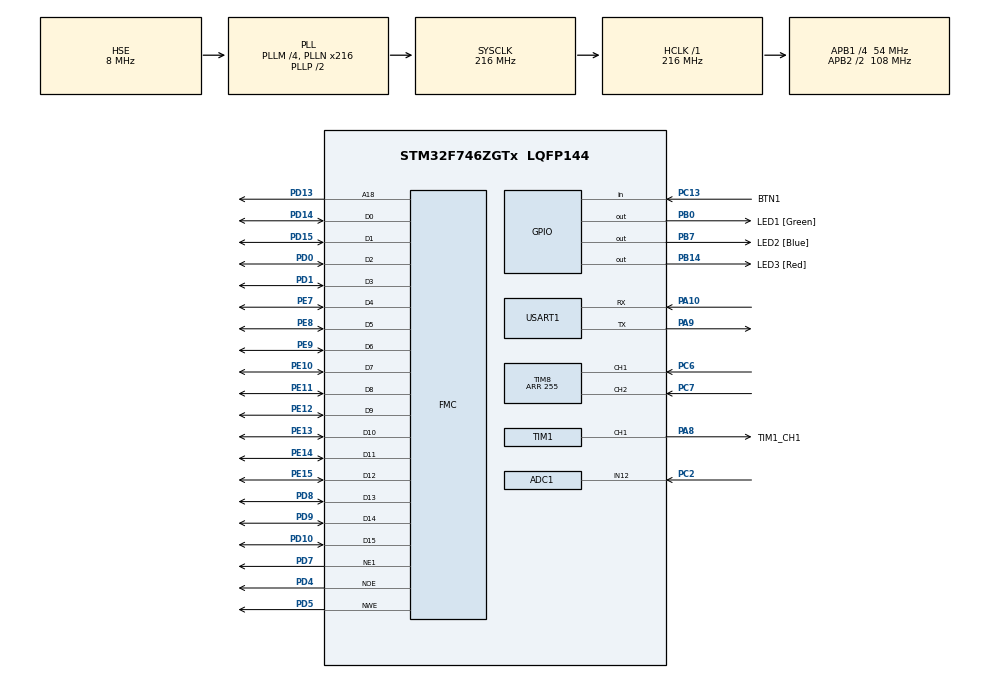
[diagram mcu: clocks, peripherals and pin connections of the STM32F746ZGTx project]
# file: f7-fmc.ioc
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ADC1.Channel-4\#ChannelRegularConversion=ADC_CHANNEL_12
ADC1.ClockPrescaler=ADC_CLOCK_SYNC_PCLK_DIV4
ADC1.ContinuousConvMode=ENABLE
ADC1.DMAContinuousRequests=ENABLE
ADC1.DataAlign=ADC_DATAALIGN_RIGHT
ADC1.DiscontinuousConvMode=DISABLE
ADC1.EOCSelection=ADC_EOC_SINGLE_CONV
ADC1.EnableAnalogWatchDog=false
ADC1.ExternalTrigConv=ADC_SOFTWARE_START
ADC1.ExternalTrigConvEdge=ADC_EXTERNALTRIGCONVEDGE_NONE
ADC1.InjNumberOfConversion=0
ADC1.NbrOfConversion=1
ADC1.NbrOfConversionFlag=1
ADC1.Rank-4\#ChannelRegularConversion=1
ADC1.Resolution=ADC_RESOLUTION_8B
ADC1.SamplingTime-4\#ChannelRegularConversion=ADC_SAMPLETIME_3CYCLES
ADC1.ScanConvMode=ENABLE
ADC1.master=1
CORTEX_M7.CPU_DCache=Disabled
CORTEX_M7.CPU_ICache=Disabled
Dma.ADC1.0.Direction=DMA_PERIPH_TO_MEMORY
Dma.ADC1.0.FIFOMode=DMA_FIFOMODE_DISABLE
Dma.ADC1.0.Instance=DMA2_Stream0
Dma.ADC1.0.MemDataAlignment=DMA_MDATAALIGN_BYTE
Dma.ADC1.0.MemInc=DMA_MINC_ENABLE
Dma.ADC1.0.Mode=DMA_CIRCULAR
Dma.ADC1.0.PeriphDataAlignment=DMA_PDATAALIGN_BYTE
Dma.ADC1.0.PeriphInc=DMA_PINC_DISABLE
Dma.ADC1.0.Priority=DMA_PRIORITY_LOW
Dma.MEMTOMEM.1.Direction=DMA_MEMORY_TO_MEMORY
Dma.MEMTOMEM.1.FIFOMode=DMA_FIFOMODE_ENABLE
Dma.MEMTOMEM.1.FIFOThreshold=DMA_FIFO_THRESHOLD_FULL
Dma.MEMTOMEM.1.Instance=DMA2_Stream1
Dma.MEMTOMEM.1.MemBurst=DMA_MBURST_SINGLE
Dma.MEMTOMEM.1.MemDataAlignment=DMA_MDATAALIGN_HALFWORD
Dma.MEMTOMEM.1.MemInc=DMA_MINC_DISABLE
Dma.MEMTOMEM.1.Mode=DMA_NORMAL
Dma.MEMTOMEM.1.PeriphBurst=DMA_PBURST_SINGLE
Dma.MEMTOMEM.1.PeriphDataAlignment=DMA_PDATAALIGN_HALFWORD
Dma.MEMTOMEM.1.PeriphInc=DMA_PINC_ENABLE
Dma.MEMTOMEM.1.Priority=DMA_PRIORITY_HIGH
Dma.Request0=ADC1
Dma.Request1=MEMTOMEM
FMC.AddressSetupTime1=3
FMC.BusTurnAroundDuration1=3
FMC.DataSetupTime1=8
FMC.ExtendedAddressSetupTime1=3
FMC.ExtendedBusTurnAroundDuration1=3
FMC.ExtendedDataSetupTime1=3
FMC.ExtendedMode1=FMC_EXTENDED_MODE_ENABLE
FMC.WriteFifo1=FMC_WRITE_FIFO_ENABLE
FMC.WriteOperation1=FMC_WRITE_OPERATION_ENABLE
Mcu.Family=STM32F7
Mcu.Name=STM32F746ZGTx
Mcu.Package=LQFP144
NVIC.DMA2_Stream0_IRQn=true\:0\:0\:false\:false\:true\:false
NVIC.PriorityGroup=NVIC_PRIORITYGROUP_4
PA10.Mode=Asynchronous
PA10.Signal=USART1_RX
PA13.GPIO_Label=TMS
PA13.Mode=Trace_Asynchronous_SW
PA13.Signal=SYS_JTMS-SWDIO
PA14.GPIO_Label=TCK
PA14.Mode=Trace_Asynchronous_SW
PA14.Signal=SYS_JTCK-SWCLK
PA8.GPIO_Label=TIM1_CH1
PA8.GPIO_PuPd=GPIO_NOPULL
PA8.GPIO_Speed=GPIO_SPEED_FREQ_VERY_HIGH
PA8.Signal=S_TIM1_CH1
PA9.Mode=Asynchronous
PA9.Signal=USART1_TX
PB0.GPIO_Label=LED1 [Green]
PB0.Signal=GPIO_Output
PB14.GPIO_Label=LED3 [Red]
PB14.Signal=GPIO_Output
PB3.GPIO_Label=SW0
PB3.Mode=Trace_Asynchronous_SW
PB3.Signal=SYS_JTDO-SWO
PB7.GPIO_Label=LED2 [Blue]
PB7.Signal=GPIO_Output
PC13.GPIO_Label=BTN1
PC13.Signal=GPIO_Input
PC2.Signal=ADCx_IN12
PC6.GPIO_PuPd=GPIO_PULLUP
PC6.Signal=S_TIM8_CH1
PC7.GPIO_PuPd=GPIO_PULLUP
PC7.Signal=S_TIM8_CH2
PD0.Signal=FMC_D2_DA2
PD1.Signal=FMC_D3_DA3
PD10.Signal=FMC_D15_DA15
PD13.Signal=FMC_A18
PD14.Signal=FMC_D0_DA0
PD15.Signal=FMC_D1_DA1
PD4.Signal=FMC_NOE
PD5.Signal=FMC_NWE
PD7.Mode=NorPsramChipSelect1_1
PD7.Signal=FMC_NE1
PD8.Signal=FMC_D13_DA13
PD9.Signal=FMC_D14_DA14
PE10.Signal=FMC_D7_DA7
PE11.Signal=FMC_D8_DA8
PE12.Signal=FMC_D9_DA9
PE13.Signal=FMC_D10_DA10
PE14.Signal=FMC_D11_DA11
PE15.Signal=FMC_D12_DA12
PE7.Signal=FMC_D4_DA4
PE8.Signal=FMC_D5_DA5
PE9.Signal=FMC_D6_DA6
PH0/OSC_IN.GPIO_Label=MCO [STM32F103CBT6_PA8]
PH0/OSC_IN.Mode=HSE-External-Oscillator
PH0/OSC_IN.Signal=RCC_OSC_IN
PH1/OSC_OUT.Mode=HSE-External-Oscillator
PH1/OSC_OUT.Signal=RCC_OSC_OUT
ProjectManager.HeapSize=0x200
ProjectManager.StackSize=0x400
ProjectManager.TargetToolchain=SW4STM32
RCC.48MHZClocksFreq_Value=24000000
RCC.AHBFreq_Value=216000000
RCC.APB1CLKDivider=RCC_HCLK_DIV4
RCC.APB1Freq_Value=54000000
RCC.APB1TimFreq_Value=108000000
RCC.APB2CLKDivider=RCC_HCLK_DIV2
RCC.APB2Freq_Value=108000000
RCC.APB2TimFreq_Value=216000000
RCC.CortexFreq_Value=216000000
RCC.EnbaleCSS=true
RCC.HCLKFreq_Value=216000000
RCC.HSE_VALUE=8000000
RCC.HSI_VALUE=16000000
RCC.LSE_VALUE=32768
RCC.PLLM=4
RCC.PLLMUL=RCC_PLL_MUL9
RCC.PLLN=216
RCC.PLLQ=9
RCC.PLLSourceVirtual=RCC_PLLSOURCE_HSE
RCC.PRESCALERUSB=RCC_USBCLKSOURCE_PLL_DIV1_5
RCC.SYSCLKFreq_VALUE=216000000
RCC.SYSCLKSource=RCC_SYSCLKSOURCE_PLLCLK
RCC.SYSCLKSourceVirtual=RCC_SYSCLKSOURCE_PLLCLK
RCC.USBFreq_Value=48000000
RCC.VCOOutputFreq_Value=432000000
SH.ADCx_IN12.0=ADC1_IN12,IN12
SH.FMC_A18.0=FMC_A18,A18_1
SH.FMC_D0_DA0.0=FMC_D0,16b-d1
SH.FMC_D10_DA10.0=FMC_D10,16b-d1
SH.FMC_D11_DA11.0=FMC_D11,16b-d1
SH.FMC_D12_DA12.0=FMC_D12,16b-d1
SH.FMC_D13_DA13.0=FMC_D13,16b-d1
SH.FMC_D14_DA14.0=FMC_D14,16b-d1
SH.FMC_D15_DA15.0=FMC_D15,16b-d1
SH.FMC_D1_DA1.0=FMC_D1,16b-d1
SH.FMC_D2_DA2.0=FMC_D2,16b-d1
SH.FMC_D3_DA3.0=FMC_D3,16b-d1
SH.FMC_D4_DA4.0=FMC_D4,16b-d1
SH.FMC_D5_DA5.0=FMC_D5,16b-d1
SH.FMC_D6_DA6.0=FMC_D6,16b-d1
SH.FMC_D7_DA7.0=FMC_D7,16b-d1
SH.FMC_D8_DA8.0=FMC_D8,16b-d1
SH.FMC_D9_DA9.0=FMC_D9,16b-d1
SH.FMC_NOE.0=FMC_NOE,Lcd1
SH.FMC_NWE.0=FMC_NWE,Lcd1
SH.S_TIM1_CH1.0=TIM1_CH1,PWM Generation1 CH1
SH.S_TIM8_CH1.0=TIM8_CH1,Encoder_Interface
SH.S_TIM8_CH2.0=TIM8_CH2,Encoder_Interface
TIM1.AutoReloadPreload=TIM_AUTORELOAD_PRELOAD_ENABLE
TIM1.Channel-PWM\ Generation1\ CH1=TIM_CHANNEL_1
TIM1.Period=99
TIM1.Prescaler=107
TIM1.Pulse-PWM\ Generation1\ CH1=30
TIM8.EncoderMode=TIM_ENCODERMODE_TI12
TIM8.IC1Filter=6
TIM8.IC2Filter=6
TIM8.Period=255
USART1.DMADisableonRxErrorParam=ADVFEATURE_DMA_DISABLEONRXERROR
USART1.OverrunDisableParam=ADVFEATURE_OVERRUN_DISABLE
USART1.VirtualMode-Asynchronous=VM_ASYNC
USART1.WordLength=WORDLENGTH_8B
VP_TIM1_VS_ClockSourceINT.Mode=Internal
board=NUCLEO-F746ZG

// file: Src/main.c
/**
  ******************************************************************************
  * @file           : main.c
  * @brief          : Main program body
  ******************************************************************************
  ** This notice applies to any and all portions of this file
  * that are not between comment pairs USER CODE BEGIN and
  * USER CODE END. Other portions of this file, whether
  * inserted by the user or by software development tools
  * are owned by their respective copyright owners.
  *
  * COPYRIGHT(c) 2018 STMicroelectronics
  *
  * Redistribution and use in source and binary forms, with or without modification,
  * are permitted provided that the following conditions are met:
  *   1. Redistributions of source code must retain the above copyright notice,
  *      this list of conditions and the following disclaimer.
  *   2. Redistributions in binary form must reproduce the above copyright notice,
  *      this list of conditions and the following disclaimer in the documentation
  *      and/or other materials provided with the distribution.
  *   3. Neither the name of STMicroelectronics nor the names of its contributors
  *      may be used to endorse or promote products derived from this software
  *      without specific prior written permission.
  *
  * THIS SOFTWARE IS PROVIDED BY THE COPYRIGHT HOLDERS AND CONTRIBUTORS "AS IS"
  * AND ANY EXPRESS OR IMPLIED WARRANTIES, INCLUDING, BUT NOT LIMITED TO, THE
  * IMPLIED WARRANTIES OF MERCHANTABILITY AND FITNESS FOR A PARTICULAR PURPOSE ARE
  * DISCLAIMED. IN NO EVENT SHALL THE COPYRIGHT HOLDER OR CONTRIBUTORS BE LIABLE
  * FOR ANY DIRECT, INDIRECT, INCIDENTAL, SPECIAL, EXEMPLARY, OR CONSEQUENTIAL
  * DAMAGES (INCLUDING, BUT NOT LIMITED TO, PROCUREMENT OF SUBSTITUTE GOODS OR
  * SERVICES; LOSS OF USE, DATA, OR PROFITS; OR BUSINESS INTERRUPTION) HOWEVER
  * CAUSED AND ON ANY THEORY OF LIABILITY, WHETHER IN CONTRACT, STRICT LIABILITY,
  * OR TORT (INCLUDING NEGLIGENCE OR OTHERWISE) ARISING IN ANY WAY OUT OF THE USE
  * OF THIS SOFTWARE, EVEN IF ADVISED OF THE POSSIBILITY OF SUCH DAMAGE.
  *
  ******************************************************************************
  */
#include "main.h"
#include "stm32f7xx_hal.h"

/* USER CODE BEGIN Includes */
#include <_main.h>
/* USER CODE END Includes */

ADC_HandleTypeDef hadc1;
DMA_HandleTypeDef hdma_adc1;

TIM_HandleTypeDef htim1;
TIM_HandleTypeDef htim8;

UART_HandleTypeDef huart1;

DMA_HandleTypeDef hdma_memtomem_dma2_stream1;
SRAM_HandleTypeDef hsram1;

/* USER CODE BEGIN PV */
/* Private variables ---------------------------------------------------------*/

/* USER CODE END PV */

void SystemClock_Config(void);
static void MX_GPIO_Init(void);
static void MX_DMA_Init(void);
static void MX_FMC_Init(void);
static void MX_ADC1_Init(void);
static void MX_TIM1_Init(void);
static void MX_USART1_UART_Init(void);
static void MX_TIM8_Init(void);

void HAL_TIM_MspPostInit(TIM_HandleTypeDef *htim);

/* USER CODE BEGIN PFP */
/* Private function prototypes -----------------------------------------------*/

/* USER CODE END PFP */

int main(void)
{

  /* MCU Configuration----------------------------------------------------------*/

  /* Reset of all peripherals, Initializes the Flash interface and the Systick. */
  HAL_Init();

  /* Configure the system clock */
  SystemClock_Config();

  /* USER CODE BEGIN SysInit */
  // FMC 0x60000000 remap to 0xC0000000 for disable ARM Core cache.
  SYSCFG->MEMRMP |= SYSCFG_MEMRMP_SWP_FMC_0;

  /* USER CODE END SysInit */

  /* Initialize all configured peripherals */
  MX_GPIO_Init();
  MX_DMA_Init();
  MX_FMC_Init();
  MX_ADC1_Init();
  MX_TIM1_Init();
  MX_USART1_UART_Init();
  MX_TIM8_Init();
  /* USER CODE BEGIN 2 */

  mainInitialize();

  /* USER CODE END 2 */

  /* Infinite loop */
  /* USER CODE BEGIN WHILE */

#pragma clang diagnostic push
#pragma clang diagnostic ignored "-Wmissing-noreturn"

  while (1)
  {
    mainCycle();
  /* USER CODE END WHILE */

  }

}

void SystemClock_Config(void)
{

  RCC_OscInitTypeDef RCC_OscInitStruct;
  RCC_ClkInitTypeDef RCC_ClkInitStruct;
  RCC_PeriphCLKInitTypeDef PeriphClkInitStruct;

    /**Configure the main internal regulator output voltage
    */
  __HAL_RCC_PWR_CLK_ENABLE();

  __HAL_PWR_VOLTAGESCALING_CONFIG(PWR_REGULATOR_VOLTAGE_SCALE1);

    /**Initializes the CPU, AHB and APB busses clocks
    */
  RCC_OscInitStruct.OscillatorType = RCC_OSCILLATORTYPE_HSE;
  RCC_OscInitStruct.HSEState = RCC_HSE_ON;
  RCC_OscInitStruct.PLL.PLLState = RCC_PLL_ON;
  RCC_OscInitStruct.PLL.PLLSource = RCC_PLLSOURCE_HSE;
  RCC_OscInitStruct.PLL.PLLM = 4;
  RCC_OscInitStruct.PLL.PLLN = 216;
  RCC_OscInitStruct.PLL.PLLP = RCC_PLLP_DIV2;
  RCC_OscInitStruct.PLL.PLLQ = 9;
  if (HAL_RCC_OscConfig(&RCC_OscInitStruct) != HAL_OK)
  {
    _Error_Handler(__FILE__, __LINE__);
  }

    /**Activate the Over-Drive mode
    */
  if (HAL_PWREx_EnableOverDrive() != HAL_OK)
  {
    _Error_Handler(__FILE__, __LINE__);
  }

    /**Initializes the CPU, AHB and APB busses clocks
    */
  RCC_ClkInitStruct.ClockType = RCC_CLOCKTYPE_HCLK|RCC_CLOCKTYPE_SYSCLK
                              |RCC_CLOCKTYPE_PCLK1|RCC_CLOCKTYPE_PCLK2;
  RCC_ClkInitStruct.SYSCLKSource = RCC_SYSCLKSOURCE_PLLCLK;
  RCC_ClkInitStruct.AHBCLKDivider = RCC_SYSCLK_DIV1;
  RCC_ClkInitStruct.APB1CLKDivider = RCC_HCLK_DIV4;
  RCC_ClkInitStruct.APB2CLKDivider = RCC_HCLK_DIV2;

  if (HAL_RCC_ClockConfig(&RCC_ClkInitStruct, FLASH_LATENCY_7) != HAL_OK)
  {
    _Error_Handler(__FILE__, __LINE__);
  }

  PeriphClkInitStruct.PeriphClockSelection = RCC_PERIPHCLK_USART1;
  PeriphClkInitStruct.Usart1ClockSelection = RCC_USART1CLKSOURCE_PCLK2;
  if (HAL_RCCEx_PeriphCLKConfig(&PeriphClkInitStruct) != HAL_OK)
  {
    _Error_Handler(__FILE__, __LINE__);
  }

    /**Enables the Clock Security System
    */
  HAL_RCC_EnableCSS();

    /**Configure the Systick interrupt time
    */
  HAL_SYSTICK_Config(HAL_RCC_GetHCLKFreq()/1000);

    /**Configure the Systick
    */
  HAL_SYSTICK_CLKSourceConfig(SYSTICK_CLKSOURCE_HCLK);

  /* SysTick_IRQn interrupt configuration */
  HAL_NVIC_SetPriority(SysTick_IRQn, 0, 0);
}

/* ADC1 init function */
static void MX_ADC1_Init(void)
{

  ADC_ChannelConfTypeDef sConfig;

    /**Configure the global features of the ADC (Clock, Resolution, Data Alignment and number of conversion)
    */
  hadc1.Instance = ADC1;
  hadc1.Init.ClockPrescaler = ADC_CLOCK_SYNC_PCLK_DIV4;
  hadc1.Init.Resolution = ADC_RESOLUTION_8B;
  hadc1.Init.ScanConvMode = ENABLE;
  hadc1.Init.ContinuousConvMode = ENABLE;
  hadc1.Init.DiscontinuousConvMode = DISABLE;
  hadc1.Init.ExternalTrigConvEdge = ADC_EXTERNALTRIGCONVEDGE_NONE;
  hadc1.Init.ExternalTrigConv = ADC_SOFTWARE_START;
  hadc1.Init.DataAlign = ADC_DATAALIGN_RIGHT;
  hadc1.Init.NbrOfConversion = 1;
  hadc1.Init.DMAContinuousRequests = ENABLE;
  hadc1.Init.EOCSelection = ADC_EOC_SINGLE_CONV;
  if (HAL_ADC_Init(&hadc1) != HAL_OK)
  {
    _Error_Handler(__FILE__, __LINE__);
  }

    /**Configure for the selected ADC regular channel its corresponding rank in the sequencer and its sample time.
    */
  sConfig.Channel = ADC_CHANNEL_12;
  sConfig.Rank = ADC_REGULAR_RANK_1;
  sConfig.SamplingTime = ADC_SAMPLETIME_3CYCLES;
  if (HAL_ADC_ConfigChannel(&hadc1, &sConfig) != HAL_OK)
  {
    _Error_Handler(__FILE__, __LINE__);
  }

}

/* TIM1 init function */
static void MX_TIM1_Init(void)
{

  TIM_ClockConfigTypeDef sClockSourceConfig;
  TIM_MasterConfigTypeDef sMasterConfig;
  TIM_OC_InitTypeDef sConfigOC;
  TIM_BreakDeadTimeConfigTypeDef sBreakDeadTimeConfig;

  htim1.Instance = TIM1;
  htim1.Init.Prescaler = 107;
  htim1.Init.CounterMode = TIM_COUNTERMODE_UP;
  htim1.Init.Period = 99;
  htim1.Init.ClockDivision = TIM_CLOCKDIVISION_DIV1;
  htim1.Init.RepetitionCounter = 0;
  htim1.Init.AutoReloadPreload = TIM_AUTORELOAD_PRELOAD_ENABLE;
  if (HAL_TIM_Base_Init(&htim1) != HAL_OK)
  {
    _Error_Handler(__FILE__, __LINE__);
  }

  sClockSourceConfig.ClockSource = TIM_CLOCKSOURCE_INTERNAL;
  if (HAL_TIM_ConfigClockSource(&htim1, &sClockSourceConfig) != HAL_OK)
  {
    _Error_Handler(__FILE__, __LINE__);
  }

  if (HAL_TIM_PWM_Init(&htim1) != HAL_OK)
  {
    _Error_Handler(__FILE__, __LINE__);
  }

  sMasterConfig.MasterOutputTrigger = TIM_TRGO_RESET;
  sMasterConfig.MasterOutputTrigger2 = TIM_TRGO2_RESET;
  sMasterConfig.MasterSlaveMode = TIM_MASTERSLAVEMODE_DISABLE;
  if (HAL_TIMEx_MasterConfigSynchronization(&htim1, &sMasterConfig) != HAL_OK)
  {
    _Error_Handler(__FILE__, __LINE__);
  }

  sConfigOC.OCMode = TIM_OCMODE_PWM1;
  sConfigOC.Pulse = 30;
  sConfigOC.OCPolarity = TIM_OCPOLARITY_HIGH;
  sConfigOC.OCNPolarity = TIM_OCNPOLARITY_HIGH;
  sConfigOC.OCFastMode = TIM_OCFAST_DISABLE;
  sConfigOC.OCIdleState = TIM_OCIDLESTATE_RESET;
  sConfigOC.OCNIdleState = TIM_OCNIDLESTATE_RESET;
  if (HAL_TIM_PWM_ConfigChannel(&htim1, &sConfigOC, TIM_CHANNEL_1) != HAL_OK)
  {
    _Error_Handler(__FILE__, __LINE__);
  }

  sBreakDeadTimeConfig.OffStateRunMode = TIM_OSSR_DISABLE;
  sBreakDeadTimeConfig.OffStateIDLEMode = TIM_OSSI_DISABLE;
  sBreakDeadTimeConfig.LockLevel = TIM_LOCKLEVEL_OFF;
  sBreakDeadTimeConfig.DeadTime = 0;
  sBreakDeadTimeConfig.BreakState = TIM_BREAK_DISABLE;
  sBreakDeadTimeConfig.BreakPolarity = TIM_BREAKPOLARITY_HIGH;
  sBreakDeadTimeConfig.BreakFilter = 0;
  sBreakDeadTimeConfig.Break2State = TIM_BREAK2_DISABLE;
  sBreakDeadTimeConfig.Break2Polarity = TIM_BREAK2POLARITY_HIGH;
  sBreakDeadTimeConfig.Break2Filter = 0;
  sBreakDeadTimeConfig.AutomaticOutput = TIM_AUTOMATICOUTPUT_DISABLE;
  if (HAL_TIMEx_ConfigBreakDeadTime(&htim1, &sBreakDeadTimeConfig) != HAL_OK)
  {
    _Error_Handler(__FILE__, __LINE__);
  }

  HAL_TIM_MspPostInit(&htim1);

}

/* TIM8 init function */
static void MX_TIM8_Init(void)
{

  TIM_Encoder_InitTypeDef sConfig;
  TIM_MasterConfigTypeDef sMasterConfig;

  htim8.Instance = TIM8;
  htim8.Init.Prescaler = 0;
  htim8.Init.CounterMode = TIM_COUNTERMODE_UP;
  htim8.Init.Period = 255;
  htim8.Init.ClockDivision = TIM_CLOCKDIVISION_DIV1;
  htim8.Init.RepetitionCounter = 0;
  htim8.Init.AutoReloadPreload = TIM_AUTORELOAD_PRELOAD_DISABLE;
  sConfig.EncoderMode = TIM_ENCODERMODE_TI12;
  sConfig.IC1Polarity = TIM_ICPOLARITY_RISING;
  sConfig.IC1Selection = TIM_ICSELECTION_DIRECTTI;
  sConfig.IC1Prescaler = TIM_ICPSC_DIV1;
  sConfig.IC1Filter = 6;
  sConfig.IC2Polarity = TIM_ICPOLARITY_RISING;
  sConfig.IC2Selection = TIM_ICSELECTION_DIRECTTI;
  sConfig.IC2Prescaler = TIM_ICPSC_DIV1;
  sConfig.IC2Filter = 6;
  if (HAL_TIM_Encoder_Init(&htim8, &sConfig) != HAL_OK)
  {
    _Error_Handler(__FILE__, __LINE__);
  }

  sMasterConfig.MasterOutputTrigger = TIM_TRGO_RESET;
  sMasterConfig.MasterOutputTrigger2 = TIM_TRGO2_RESET;
  sMasterConfig.MasterSlaveMode = TIM_MASTERSLAVEMODE_DISABLE;
  if (HAL_TIMEx_MasterConfigSynchronization(&htim8, &sMasterConfig) != HAL_OK)
  {
    _Error_Handler(__FILE__, __LINE__);
  }

}

/* USART1 init function */
static void MX_USART1_UART_Init(void)
{

  huart1.Instance = USART1;
  huart1.Init.BaudRate = 115200;
  huart1.Init.WordLength = UART_WORDLENGTH_8B;
  huart1.Init.StopBits = UART_STOPBITS_1;
  huart1.Init.Parity = UART_PARITY_NONE;
  huart1.Init.Mode = UART_MODE_TX_RX;
  huart1.Init.HwFlowCtl = UART_HWCONTROL_NONE;
  huart1.Init.OverSampling = UART_OVERSAMPLING_16;
  huart1.Init.OneBitSampling = UART_ONE_BIT_SAMPLE_DISABLE;
  huart1.AdvancedInit.AdvFeatureInit = UART_ADVFEATURE_RXOVERRUNDISABLE_INIT|UART_ADVFEATURE_DMADISABLEONERROR_INIT;
  huart1.AdvancedInit.OverrunDisable = UART_ADVFEATURE_OVERRUN_DISABLE;
  huart1.AdvancedInit.DMADisableonRxError = UART_ADVFEATURE_DMA_DISABLEONRXERROR;
  if (HAL_UART_Init(&huart1) != HAL_OK)
  {
    _Error_Handler(__FILE__, __LINE__);
  }

}

static void MX_DMA_Init(void)
{
  /* DMA controller clock enable */
  __HAL_RCC_DMA2_CLK_ENABLE();

  /* Configure DMA request hdma_memtomem_dma2_stream1 on DMA2_Stream1 */
  hdma_memtomem_dma2_stream1.Instance = DMA2_Stream1;
  hdma_memtomem_dma2_stream1.Init.Channel = DMA_CHANNEL_0;
  hdma_memtomem_dma2_stream1.Init.Direction = DMA_MEMORY_TO_MEMORY;
  hdma_memtomem_dma2_stream1.Init.PeriphInc = DMA_PINC_ENABLE;
  hdma_memtomem_dma2_stream1.Init.MemInc = DMA_MINC_DISABLE;
  hdma_memtomem_dma2_stream1.Init.PeriphDataAlignment = DMA_PDATAALIGN_HALFWORD;
  hdma_memtomem_dma2_stream1.Init.MemDataAlignment = DMA_MDATAALIGN_HALFWORD;
  hdma_memtomem_dma2_stream1.Init.Mode = DMA_NORMAL;
  hdma_memtomem_dma2_stream1.Init.Priority = DMA_PRIORITY_HIGH;
  hdma_memtomem_dma2_stream1.Init.FIFOMode = DMA_FIFOMODE_ENABLE;
  hdma_memtomem_dma2_stream1.Init.FIFOThreshold = DMA_FIFO_THRESHOLD_FULL;
  hdma_memtomem_dma2_stream1.Init.MemBurst = DMA_MBURST_SINGLE;
  hdma_memtomem_dma2_stream1.Init.PeriphBurst = DMA_PBURST_SINGLE;
  if (HAL_DMA_Init(&hdma_memtomem_dma2_stream1) != HAL_OK)
  {
    _Error_Handler(__FILE__, __LINE__);
  }

  /* DMA interrupt init */
  /* DMA2_Stream0_IRQn interrupt configuration */
  HAL_NVIC_SetPriority(DMA2_Stream0_IRQn, 0, 0);
  HAL_NVIC_EnableIRQ(DMA2_Stream0_IRQn);

}
/* FMC initialization function */
static void MX_FMC_Init(void)
{
  FMC_NORSRAM_TimingTypeDef Timing;
  FMC_NORSRAM_TimingTypeDef ExtTiming;

  /** Perform the SRAM1 memory initialization sequence
  */
  hsram1.Instance = FMC_NORSRAM_DEVICE;
  hsram1.Extended = FMC_NORSRAM_EXTENDED_DEVICE;
  /* hsram1.Init */
  hsram1.Init.NSBank = FMC_NORSRAM_BANK1;
  hsram1.Init.DataAddressMux = FMC_DATA_ADDRESS_MUX_DISABLE;
  hsram1.Init.MemoryType = FMC_MEMORY_TYPE_SRAM;
  hsram1.Init.MemoryDataWidth = FMC_NORSRAM_MEM_BUS_WIDTH_16;
  hsram1.Init.BurstAccessMode = FMC_BURST_ACCESS_MODE_DISABLE;
  hsram1.Init.WaitSignalPolarity = FMC_WAIT_SIGNAL_POLARITY_LOW;
  hsram1.Init.WaitSignalActive = FMC_WAIT_TIMING_BEFORE_WS;
  hsram1.Init.WriteOperation = FMC_WRITE_OPERATION_ENABLE;
  hsram1.Init.WaitSignal = FMC_WAIT_SIGNAL_DISABLE;
  hsram1.Init.ExtendedMode = FMC_EXTENDED_MODE_ENABLE;
  hsram1.Init.AsynchronousWait = FMC_ASYNCHRONOUS_WAIT_DISABLE;
  hsram1.Init.WriteBurst = FMC_WRITE_BURST_DISABLE;
  hsram1.Init.ContinuousClock = FMC_CONTINUOUS_CLOCK_SYNC_ONLY;
  hsram1.Init.WriteFifo = FMC_WRITE_FIFO_ENABLE;
  hsram1.Init.PageSize = FMC_PAGE_SIZE_NONE;
  /* Timing */
  Timing.AddressSetupTime = 3;
  Timing.AddressHoldTime = 15;
  Timing.DataSetupTime = 8;
  Timing.BusTurnAroundDuration = 3;
  Timing.CLKDivision = 16;
  Timing.DataLatency = 17;
  Timing.AccessMode = FMC_ACCESS_MODE_A;
  /* ExtTiming */
  ExtTiming.AddressSetupTime = 3;
  ExtTiming.AddressHoldTime = 15;
  ExtTiming.DataSetupTime = 3;
  ExtTiming.BusTurnAroundDuration = 3;
  ExtTiming.CLKDivision = 16;
  ExtTiming.DataLatency = 17;
  ExtTiming.AccessMode = FMC_ACCESS_MODE_A;

  if (HAL_SRAM_Init(&hsram1, &Timing, &ExtTiming) != HAL_OK)
  {
    _Error_Handler(__FILE__, __LINE__);
  }

}

/** Configure pins as
        * Analog
        * Input
        * Output
        * EVENT_OUT
        * EXTI
*/
static void MX_GPIO_Init(void)
{

  GPIO_InitTypeDef GPIO_InitStruct;

  /* GPIO Ports Clock Enable */
  __HAL_RCC_GPIOC_CLK_ENABLE();
  __HAL_RCC_GPIOH_CLK_ENABLE();
  __HAL_RCC_GPIOB_CLK_ENABLE();
  __HAL_RCC_GPIOE_CLK_ENABLE();
  __HAL_RCC_GPIOD_CLK_ENABLE();
  __HAL_RCC_GPIOA_CLK_ENABLE();

  /*Configure GPIO pin Output Level */
  HAL_GPIO_WritePin(GPIOB, LED1_Pin|LED3_Pin|LED2_Pin, GPIO_PIN_RESET);

  /*Configure GPIO pin : BTN1_Pin */
  GPIO_InitStruct.Pin = BTN1_Pin;
  GPIO_InitStruct.Mode = GPIO_MODE_INPUT;
  GPIO_InitStruct.Pull = GPIO_NOPULL;
  HAL_GPIO_Init(BTN1_GPIO_Port, &GPIO_InitStruct);

  /*Configure GPIO pins : LED1_Pin LED3_Pin LED2_Pin */
  GPIO_InitStruct.Pin = LED1_Pin|LED3_Pin|LED2_Pin;
  GPIO_InitStruct.Mode = GPIO_MODE_OUTPUT_PP;
  GPIO_InitStruct.Pull = GPIO_NOPULL;
  GPIO_InitStruct.Speed = GPIO_SPEED_FREQ_LOW;
  HAL_GPIO_Init(GPIOB, &GPIO_InitStruct);

}

void _Error_Handler(char *file, int line)
{
  /* USER CODE BEGIN Error_Handler_Debug */
  /* User can add his own implementation to report the HAL error return state */
  char msg[200];
  sprintf(msg, "\r\nError_Handler.\r\nFile: %s\r\nLine: %i\r\n", file, line);
  DBG_Trace(msg);

  while(1)
  {
  }
  /* USER CODE END Error_Handler_Debug */
}

/************************ (C) COPYRIGHT STMicroelectronics *****END OF FILE****/
